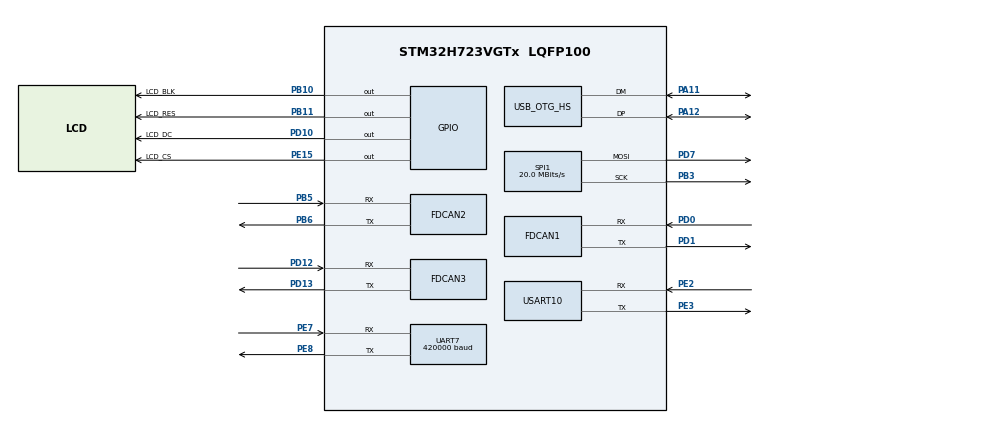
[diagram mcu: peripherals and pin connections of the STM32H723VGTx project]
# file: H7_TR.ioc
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CORTEX_M7.CPU_DCache=Enabled
CORTEX_M7.CPU_ICache=Enabled
CORTEX_M7.default_mode_Activation=1
FDCAN1.AutoRetransmission=ENABLE
FDCAN1.CalculateBaudRateNominal=1000000
FDCAN1.CalculateTimeBitNominal=1000
FDCAN1.CalculateTimeQuantumNominal=12.5
FDCAN1.DataPrescaler=1
FDCAN1.ExtFiltersNbr=4
FDCAN1.NominalPrescaler=1
FDCAN1.NominalSyncJumpWidth=20
FDCAN1.NominalTimeSeg1=59
FDCAN1.NominalTimeSeg2=20
FDCAN1.ProtocolException=ENABLE
FDCAN1.RxFifo0ElmtsNbr=8
FDCAN1.RxFifo1ElmtsNbr=8
FDCAN1.StdFiltersNbr=4
FDCAN1.TxFifoQueueElmtsNbr=8
FDCAN2.AutoRetransmission=ENABLE
FDCAN2.CalculateBaudRateNominal=1000000
FDCAN2.CalculateTimeBitNominal=1000
FDCAN2.CalculateTimeQuantumNominal=12.5
FDCAN2.ExtFiltersNbr=4
FDCAN2.MessageRAMOffset=1030
FDCAN2.NominalPrescaler=1
FDCAN2.NominalSyncJumpWidth=20
FDCAN2.NominalTimeSeg1=59
FDCAN2.NominalTimeSeg2=20
FDCAN2.ProtocolException=ENABLE
FDCAN2.RxFifo0ElmtsNbr=8
FDCAN2.RxFifo1ElmtsNbr=8
FDCAN2.StdFiltersNbr=4
FDCAN2.TxFifoQueueElmtsNbr=8
FDCAN3.AutoRetransmission=ENABLE
FDCAN3.CalculateBaudRateNominal=1000000
FDCAN3.CalculateTimeBitNominal=1000
FDCAN3.CalculateTimeQuantumNominal=12.5
FDCAN3.ExtFiltersNbr=4
FDCAN3.MessageRAMOffset=2066
FDCAN3.NominalPrescaler=1
FDCAN3.NominalSyncJumpWidth=20
FDCAN3.NominalTimeSeg1=59
FDCAN3.NominalTimeSeg2=20
FDCAN3.ProtocolException=ENABLE
FDCAN3.RxFifo0ElmtsNbr=8
FDCAN3.RxFifo1ElmtsNbr=8
FDCAN3.StdFiltersNbr=4
FDCAN3.TxFifoQueueElmtsNbr=8
Mcu.Family=STM32H7
Mcu.Name=STM32H723VGTx
Mcu.Package=LQFP100
NVIC.FDCAN1_IT0_IRQn=true\:0\:0\:false\:false\:true\:true\:true\:true
NVIC.FDCAN2_IT0_IRQn=true\:0\:0\:false\:false\:true\:true\:true\:true
NVIC.FDCAN3_IT0_IRQn=true\:0\:0\:false\:false\:true\:true\:true\:true
NVIC.OTG_HS_IRQn=true\:0\:0\:false\:false\:true\:false\:true\:true
NVIC.PriorityGroup=NVIC_PRIORITYGROUP_4
NVIC.TIM6_DAC_IRQn=true\:1\:0\:true\:false\:true\:true\:true\:true
NVIC.UART7_IRQn=true\:0\:0\:false\:false\:true\:true\:true\:true
NVIC.USART10_IRQn=true\:0\:0\:false\:false\:true\:true\:true\:true
PA11.Mode=Device_Only_FS
PA11.Signal=USB_OTG_HS_DM
PA12.Mode=Device_Only_FS
PA12.Signal=USB_OTG_HS_DP
PA13(JTMS/SWDIO).Mode=Serial_Wire
PA13(JTMS/SWDIO).Signal=DEBUG_JTMS-SWDIO
PA14(JTCK/SWCLK).Mode=Serial_Wire
PA14(JTCK/SWCLK).Signal=DEBUG_JTCK-SWCLK
PB10.GPIO_Label=LCD_BLK
PB10.GPIO_PuPd=GPIO_NOPULL
PB10.Signal=GPIO_Output
PB11.GPIO_Label=LCD_RES
PB11.PinState=GPIO_PIN_SET
PB11.Signal=GPIO_Output
PB3(JTDO/TRACESWO).Mode=TX_Only_Simplex_Unidirect_Master
PB3(JTDO/TRACESWO).Signal=SPI1_SCK
PB5.Mode=FDCAN_Activate
PB5.Signal=FDCAN2_RX
PB6.Mode=FDCAN_Activate
PB6.Signal=FDCAN2_TX
PD0.Mode=FDCAN_Activate
PD0.Signal=FDCAN1_RX
PD1.Mode=FDCAN_Activate
PD1.Signal=FDCAN1_TX
PD10.GPIO_Label=LCD_DC
PD10.GPIO_Speed=GPIO_SPEED_FREQ_VERY_HIGH
PD10.PinState=GPIO_PIN_SET
PD10.Signal=GPIO_Output
PD12.Mode=FDCAN_Activate
PD12.Signal=FDCAN3_RX
PD13.Mode=FDCAN_Activate
PD13.Signal=FDCAN3_TX
PD7.Mode=TX_Only_Simplex_Unidirect_Master
PD7.Signal=SPI1_MOSI
PE15.GPIO_Label=LCD_CS
PE15.GPIO_Speed=GPIO_SPEED_FREQ_VERY_HIGH
PE15.PinState=GPIO_PIN_SET
PE15.Signal=GPIO_Output
PE2.GPIO_PuPd=GPIO_PULLUP
PE2.Mode=Asynchronous
PE2.Signal=USART10_RX
PE3.Mode=Asynchronous
PE3.Signal=USART10_TX
PE7.GPIO_PuPd=GPIO_PULLUP
PE7.Mode=Asynchronous
PE7.Signal=UART7_RX
PE8.Mode=Asynchronous
PE8.Signal=UART7_TX
PH0-OSC_IN.Mode=HSE-External-Oscillator
PH0-OSC_IN.Signal=RCC_OSC_IN
PH1-OSC_OUT.Mode=HSE-External-Oscillator
PH1-OSC_OUT.Signal=RCC_OSC_OUT
ProjectManager.HeapSize=0x1000
ProjectManager.StackSize=0x1000
ProjectManager.TargetToolchain=CMake
RCC.ADCFreq_Value=48375000
RCC.APB1Freq_Value=120000000
RCC.APB2Freq_Value=120000000
RCC.APB3Freq_Value=120000000
RCC.APB4Freq_Value=120000000
RCC.CortexFreq_Value=480000000
RCC.D1PPRE=RCC_APB3_DIV2
RCC.D2PPRE1=RCC_APB1_DIV2
RCC.D2PPRE2=RCC_APB2_DIV2
RCC.D3PPRE=RCC_APB4_DIV2
RCC.DIVM1=2
RCC.DIVN1=40
RCC.DIVP1=1
RCC.DIVQ1=6
RCC.HCLKFreq_Value=240000000
RCC.HPRE=RCC_HCLK_DIV2
RCC.HSE_VALUE=24000000
RCC.PLLFRACN=0
RCC.PLLSourceVirtual=RCC_PLLSOURCE_HSE
RCC.SYSCLKFreq_VALUE=480000000
RCC.SYSCLKSource=RCC_SYSCLKSOURCE_PLLCLK
RCC.USBCLockSelection=RCC_USBCLKSOURCE_HSI48
RCC.USBFreq_Value=48000000
SPI1.BaudRatePrescaler=SPI_BAUDRATEPRESCALER_4
SPI1.CLKPolarity=SPI_POLARITY_HIGH
SPI1.CalculateBaudRate=20.0 MBits/s
SPI1.DataSize=SPI_DATASIZE_8BIT
SPI1.Direction=SPI_DIRECTION_2LINES_TXONLY
SPI1.MasterKeepIOState=SPI_MASTER_KEEP_IO_STATE_ENABLE
SPI1.Mode=SPI_MODE_MASTER
SPI1.VirtualType=VM_MASTER
TIM6.AutoReloadPreload=TIM_AUTORELOAD_PRELOAD_ENABLE
TIM6.Period=999
TIM6.Prescaler=239
UART7.BaudRate=420000
USART10.VirtualMode=VM_ASYNC
USB_DEVICE.CLASS_NAME_HS=CDC
USB_DEVICE.VirtualMode=Cdc
USB_DEVICE.VirtualModeHS=Cdc_HS
USB_OTG_HS.VirtualMode-Device_Only_FS=Device_Only_FS
VP_MEMORYMAP_VS_MEMORYMAP.Mode=CurAppReg
VP_TIM6_VS_ClockSourceINT.Mode=Enable_Timer
VP_USB_DEVICE_VS_USB_DEVICE_CDC_HS.Mode=CDC_HS
board=custom

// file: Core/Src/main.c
/* USER CODE BEGIN Header */
/**
 ******************************************************************************
 * @file           : main.c
 * @brief          : Main program body
 ******************************************************************************
 * @attention
 *
 * Copyright (c) 2026 STMicroelectronics.
 * All rights reserved.
 *wawa
 * This software is licensed under terms that can be found in the LICENSE file
 * in the root directory of this software component.
 * If no LICENSE file comes with this software, it is provided AS-IS.
 *
 ******************************************************************************
 */
/* USER CODE END Header */
#include "main.h"
#include "usb_device.h"

/* USER CODE BEGIN Includes */
#include "J4340.h"
#include "app_main.h"
#include "motor_cfg.h"
#include "motor_ctrl.h"
/* USER CODE END Includes */

FDCAN_HandleTypeDef hfdcan1;
FDCAN_HandleTypeDef hfdcan2;
FDCAN_HandleTypeDef hfdcan3;

SPI_HandleTypeDef hspi1;

TIM_HandleTypeDef htim6;

UART_HandleTypeDef huart7;
UART_HandleTypeDef huart10;

void SystemClock_Config(void);
static void MPU_Config(void);
static void MX_GPIO_Init(void);
static void MX_FDCAN1_Init(void);
static void MX_FDCAN2_Init(void);
static void MX_FDCAN3_Init(void);
static void MX_TIM6_Init(void);
static void MX_SPI1_Init(void);
static void MX_UART7_Init(void);
static void MX_USART10_UART_Init(void);

int main(void) {

  /* MPU Configuration--------------------------------------------------------*/
  MPU_Config();

  /* Enable the CPU Cache */

  /* Enable I-Cache---------------------------------------------------------*/
  SCB_EnableICache();

  /* Enable D-Cache---------------------------------------------------------*/
  SCB_EnableDCache();

  /* MCU Configuration--------------------------------------------------------*/

  /* Reset of all peripherals, Initializes the Flash interface and the Systick.
   */
  HAL_Init();

  /* Configure the system clock */
  SystemClock_Config();

  /* Initialize all configured peripherals */
  MX_GPIO_Init();
  MX_FDCAN1_Init();
  MX_FDCAN2_Init();
  MX_FDCAN3_Init();
  MX_USB_DEVICE_Init();
  MX_TIM6_Init();
  MX_SPI1_Init();
  MX_UART7_Init();
  MX_USART10_UART_Init();
  /* USER CODE BEGIN 2 */
  app_init();
  FDCAN1_Filter_Init();
  DM4340_Init();
  /* USER CODE END 2 */

  /* Infinite loop */
  while (1) {

    /* USER CODE BEGIN 3 */
    app_loop();
    DM4340_Task();
    // motor_ctrl_set_pos(MOTOR_M2006_1, 90.0f, 30.0f);
  }
  /* USER CODE END 3 */
}

void SystemClock_Config(void) {
  RCC_OscInitTypeDef RCC_OscInitStruct = {0};
  RCC_ClkInitTypeDef RCC_ClkInitStruct = {0};

  /** Supply configuration update enable
   */
  HAL_PWREx_ConfigSupply(PWR_LDO_SUPPLY);

  /** Configure the main internal regulator output voltage
   */
  __HAL_PWR_VOLTAGESCALING_CONFIG(PWR_REGULATOR_VOLTAGE_SCALE0);

  while (!__HAL_PWR_GET_FLAG(PWR_FLAG_VOSRDY)) {
  }

  /** Initializes the RCC Oscillators according to the specified parameters
   * in the RCC_OscInitTypeDef structure.
   */
  RCC_OscInitStruct.OscillatorType =
      RCC_OSCILLATORTYPE_HSI48 | RCC_OSCILLATORTYPE_HSE;
  RCC_OscInitStruct.HSEState = RCC_HSE_ON;
  RCC_OscInitStruct.HSI48State = RCC_HSI48_ON;
  RCC_OscInitStruct.PLL.PLLState = RCC_PLL_ON;
  RCC_OscInitStruct.PLL.PLLSource = RCC_PLLSOURCE_HSE;
  RCC_OscInitStruct.PLL.PLLM = 2;
  RCC_OscInitStruct.PLL.PLLN = 40;
  RCC_OscInitStruct.PLL.PLLP = 1;
  RCC_OscInitStruct.PLL.PLLQ = 6;
  RCC_OscInitStruct.PLL.PLLR = 2;
  RCC_OscInitStruct.PLL.PLLRGE = RCC_PLL1VCIRANGE_3;
  RCC_OscInitStruct.PLL.PLLVCOSEL = RCC_PLL1VCOWIDE;
  RCC_OscInitStruct.PLL.PLLFRACN = 0;
  if (HAL_RCC_OscConfig(&RCC_OscInitStruct) != HAL_OK) {
    Error_Handler();
  }

  /** Initializes the CPU, AHB and APB buses clocks
   */
  RCC_ClkInitStruct.ClockType = RCC_CLOCKTYPE_HCLK | RCC_CLOCKTYPE_SYSCLK |
                                RCC_CLOCKTYPE_PCLK1 | RCC_CLOCKTYPE_PCLK2 |
                                RCC_CLOCKTYPE_D3PCLK1 | RCC_CLOCKTYPE_D1PCLK1;
  RCC_ClkInitStruct.SYSCLKSource = RCC_SYSCLKSOURCE_PLLCLK;
  RCC_ClkInitStruct.SYSCLKDivider = RCC_SYSCLK_DIV1;
  RCC_ClkInitStruct.AHBCLKDivider = RCC_HCLK_DIV2;
  RCC_ClkInitStruct.APB3CLKDivider = RCC_APB3_DIV2;
  RCC_ClkInitStruct.APB1CLKDivider = RCC_APB1_DIV2;
  RCC_ClkInitStruct.APB2CLKDivider = RCC_APB2_DIV2;
  RCC_ClkInitStruct.APB4CLKDivider = RCC_APB4_DIV2;

  if (HAL_RCC_ClockConfig(&RCC_ClkInitStruct, FLASH_LATENCY_3) != HAL_OK) {
    Error_Handler();
  }
}

static void MX_FDCAN1_Init(void) {

  hfdcan1.Instance = FDCAN1;
  hfdcan1.Init.FrameFormat = FDCAN_FRAME_CLASSIC;
  hfdcan1.Init.Mode = FDCAN_MODE_NORMAL;
  hfdcan1.Init.AutoRetransmission = ENABLE;
  hfdcan1.Init.TransmitPause = DISABLE;
  hfdcan1.Init.ProtocolException = ENABLE;
  hfdcan1.Init.NominalPrescaler = 1;
  hfdcan1.Init.NominalSyncJumpWidth = 20;
  hfdcan1.Init.NominalTimeSeg1 = 59;
  hfdcan1.Init.NominalTimeSeg2 = 20;
  hfdcan1.Init.DataPrescaler = 1;
  hfdcan1.Init.DataSyncJumpWidth = 1;
  hfdcan1.Init.DataTimeSeg1 = 1;
  hfdcan1.Init.DataTimeSeg2 = 1;
  hfdcan1.Init.MessageRAMOffset = 0;
  hfdcan1.Init.StdFiltersNbr = 4;
  hfdcan1.Init.ExtFiltersNbr = 4;
  hfdcan1.Init.RxFifo0ElmtsNbr = 8;
  hfdcan1.Init.RxFifo0ElmtSize = FDCAN_DATA_BYTES_8;
  hfdcan1.Init.RxFifo1ElmtsNbr = 8;
  hfdcan1.Init.RxFifo1ElmtSize = FDCAN_DATA_BYTES_8;
  hfdcan1.Init.RxBuffersNbr = 0;
  hfdcan1.Init.RxBufferSize = FDCAN_DATA_BYTES_8;
  hfdcan1.Init.TxEventsNbr = 0;
  hfdcan1.Init.TxBuffersNbr = 0;
  hfdcan1.Init.TxFifoQueueElmtsNbr = 8;
  hfdcan1.Init.TxFifoQueueMode = FDCAN_TX_FIFO_OPERATION;
  hfdcan1.Init.TxElmtSize = FDCAN_DATA_BYTES_8;
  if (HAL_FDCAN_Init(&hfdcan1) != HAL_OK) {
    Error_Handler();
  }
}

static void MX_FDCAN2_Init(void) {

  hfdcan2.Instance = FDCAN2;
  hfdcan2.Init.FrameFormat = FDCAN_FRAME_CLASSIC;
  hfdcan2.Init.Mode = FDCAN_MODE_NORMAL;
  hfdcan2.Init.AutoRetransmission = ENABLE;
  hfdcan2.Init.TransmitPause = DISABLE;
  hfdcan2.Init.ProtocolException = ENABLE;
  hfdcan2.Init.NominalPrescaler = 1;
  hfdcan2.Init.NominalSyncJumpWidth = 20;
  hfdcan2.Init.NominalTimeSeg1 = 59;
  hfdcan2.Init.NominalTimeSeg2 = 20;
  hfdcan2.Init.DataPrescaler = 1;
  hfdcan2.Init.DataSyncJumpWidth = 1;
  hfdcan2.Init.DataTimeSeg1 = 1;
  hfdcan2.Init.DataTimeSeg2 = 1;
  hfdcan2.Init.MessageRAMOffset = 1030;
  hfdcan2.Init.StdFiltersNbr = 4;
  hfdcan2.Init.ExtFiltersNbr = 4;
  hfdcan2.Init.RxFifo0ElmtsNbr = 8;
  hfdcan2.Init.RxFifo0ElmtSize = FDCAN_DATA_BYTES_8;
  hfdcan2.Init.RxFifo1ElmtsNbr = 8;
  hfdcan2.Init.RxFifo1ElmtSize = FDCAN_DATA_BYTES_8;
  hfdcan2.Init.RxBuffersNbr = 0;
  hfdcan2.Init.RxBufferSize = FDCAN_DATA_BYTES_8;
  hfdcan2.Init.TxEventsNbr = 0;
  hfdcan2.Init.TxBuffersNbr = 0;
  hfdcan2.Init.TxFifoQueueElmtsNbr = 8;
  hfdcan2.Init.TxFifoQueueMode = FDCAN_TX_FIFO_OPERATION;
  hfdcan2.Init.TxElmtSize = FDCAN_DATA_BYTES_8;
  if (HAL_FDCAN_Init(&hfdcan2) != HAL_OK) {
    Error_Handler();
  }
}

static void MX_FDCAN3_Init(void) {

  hfdcan3.Instance = FDCAN3;
  hfdcan3.Init.FrameFormat = FDCAN_FRAME_CLASSIC;
  hfdcan3.Init.Mode = FDCAN_MODE_NORMAL;
  hfdcan3.Init.AutoRetransmission = ENABLE;
  hfdcan3.Init.TransmitPause = DISABLE;
  hfdcan3.Init.ProtocolException = ENABLE;
  hfdcan3.Init.NominalPrescaler = 1;
  hfdcan3.Init.NominalSyncJumpWidth = 20;
  hfdcan3.Init.NominalTimeSeg1 = 59;
  hfdcan3.Init.NominalTimeSeg2 = 20;
  hfdcan3.Init.DataPrescaler = 1;
  hfdcan3.Init.DataSyncJumpWidth = 1;
  hfdcan3.Init.DataTimeSeg1 = 1;
  hfdcan3.Init.DataTimeSeg2 = 1;
  hfdcan3.Init.MessageRAMOffset = 2066;
  hfdcan3.Init.StdFiltersNbr = 4;
  hfdcan3.Init.ExtFiltersNbr = 4;
  hfdcan3.Init.RxFifo0ElmtsNbr = 8;
  hfdcan3.Init.RxFifo0ElmtSize = FDCAN_DATA_BYTES_8;
  hfdcan3.Init.RxFifo1ElmtsNbr = 8;
  hfdcan3.Init.RxFifo1ElmtSize = FDCAN_DATA_BYTES_8;
  hfdcan3.Init.RxBuffersNbr = 0;
  hfdcan3.Init.RxBufferSize = FDCAN_DATA_BYTES_8;
  hfdcan3.Init.TxEventsNbr = 0;
  hfdcan3.Init.TxBuffersNbr = 0;
  hfdcan3.Init.TxFifoQueueElmtsNbr = 8;
  hfdcan3.Init.TxFifoQueueMode = FDCAN_TX_FIFO_OPERATION;
  hfdcan3.Init.TxElmtSize = FDCAN_DATA_BYTES_8;
  if (HAL_FDCAN_Init(&hfdcan3) != HAL_OK) {
    Error_Handler();
  }
}

static void MX_SPI1_Init(void) {

  /* SPI1 parameter configuration*/
  hspi1.Instance = SPI1;
  hspi1.Init.Mode = SPI_MODE_MASTER;
  hspi1.Init.Direction = SPI_DIRECTION_2LINES_TXONLY;
  hspi1.Init.DataSize = SPI_DATASIZE_8BIT;
  hspi1.Init.CLKPolarity = SPI_POLARITY_HIGH;
  hspi1.Init.CLKPhase = SPI_PHASE_1EDGE;
  hspi1.Init.NSS = SPI_NSS_SOFT;
  hspi1.Init.BaudRatePrescaler = SPI_BAUDRATEPRESCALER_4;
  hspi1.Init.FirstBit = SPI_FIRSTBIT_MSB;
  hspi1.Init.TIMode = SPI_TIMODE_DISABLE;
  hspi1.Init.CRCCalculation = SPI_CRCCALCULATION_DISABLE;
  hspi1.Init.CRCPolynomial = 0x0;
  hspi1.Init.NSSPMode = SPI_NSS_PULSE_ENABLE;
  hspi1.Init.NSSPolarity = SPI_NSS_POLARITY_LOW;
  hspi1.Init.FifoThreshold = SPI_FIFO_THRESHOLD_01DATA;
  hspi1.Init.TxCRCInitializationPattern =
      SPI_CRC_INITIALIZATION_ALL_ZERO_PATTERN;
  hspi1.Init.RxCRCInitializationPattern =
      SPI_CRC_INITIALIZATION_ALL_ZERO_PATTERN;
  hspi1.Init.MasterSSIdleness = SPI_MASTER_SS_IDLENESS_00CYCLE;
  hspi1.Init.MasterInterDataIdleness = SPI_MASTER_INTERDATA_IDLENESS_00CYCLE;
  hspi1.Init.MasterReceiverAutoSusp = SPI_MASTER_RX_AUTOSUSP_DISABLE;
  hspi1.Init.MasterKeepIOState = SPI_MASTER_KEEP_IO_STATE_ENABLE;
  hspi1.Init.IOSwap = SPI_IO_SWAP_DISABLE;
  if (HAL_SPI_Init(&hspi1) != HAL_OK) {
    Error_Handler();
  }
}

static void MX_TIM6_Init(void) {

  TIM_MasterConfigTypeDef sMasterConfig = {0};

  htim6.Instance = TIM6;
  htim6.Init.Prescaler = 239;
  htim6.Init.CounterMode = TIM_COUNTERMODE_UP;
  htim6.Init.Period = 999;
  htim6.Init.AutoReloadPreload = TIM_AUTORELOAD_PRELOAD_ENABLE;
  if (HAL_TIM_Base_Init(&htim6) != HAL_OK) {
    Error_Handler();
  }
  sMasterConfig.MasterOutputTrigger = TIM_TRGO_RESET;
  sMasterConfig.MasterSlaveMode = TIM_MASTERSLAVEMODE_DISABLE;
  if (HAL_TIMEx_MasterConfigSynchronization(&htim6, &sMasterConfig) != HAL_OK) {
    Error_Handler();
  }
}

static void MX_UART7_Init(void) {

  huart7.Instance = UART7;
  huart7.Init.BaudRate = 420000;
  huart7.Init.WordLength = UART_WORDLENGTH_8B;
  huart7.Init.StopBits = UART_STOPBITS_1;
  huart7.Init.Parity = UART_PARITY_NONE;
  huart7.Init.Mode = UART_MODE_TX_RX;
  huart7.Init.HwFlowCtl = UART_HWCONTROL_NONE;
  huart7.Init.OverSampling = UART_OVERSAMPLING_16;
  huart7.Init.OneBitSampling = UART_ONE_BIT_SAMPLE_DISABLE;
  huart7.Init.ClockPrescaler = UART_PRESCALER_DIV1;
  huart7.AdvancedInit.AdvFeatureInit = UART_ADVFEATURE_NO_INIT;
  if (HAL_UART_Init(&huart7) != HAL_OK) {
    Error_Handler();
  }
  if (HAL_UARTEx_SetTxFifoThreshold(&huart7, UART_TXFIFO_THRESHOLD_1_8) !=
      HAL_OK) {
    Error_Handler();
  }
  if (HAL_UARTEx_SetRxFifoThreshold(&huart7, UART_RXFIFO_THRESHOLD_1_8) !=
      HAL_OK) {
    Error_Handler();
  }
  if (HAL_UARTEx_DisableFifoMode(&huart7) != HAL_OK) {
    Error_Handler();
  }
}

static void MX_USART10_UART_Init(void) {

  huart10.Instance = USART10;
  huart10.Init.BaudRate = 115200;
  huart10.Init.WordLength = UART_WORDLENGTH_8B;
  huart10.Init.StopBits = UART_STOPBITS_1;
  huart10.Init.Parity = UART_PARITY_NONE;
  huart10.Init.Mode = UART_MODE_TX_RX;
  huart10.Init.HwFlowCtl = UART_HWCONTROL_NONE;
  huart10.Init.OverSampling = UART_OVERSAMPLING_16;
  huart10.Init.OneBitSampling = UART_ONE_BIT_SAMPLE_DISABLE;
  huart10.Init.ClockPrescaler = UART_PRESCALER_DIV1;
  huart10.AdvancedInit.AdvFeatureInit = UART_ADVFEATURE_NO_INIT;
  if (HAL_UART_Init(&huart10) != HAL_OK) {
    Error_Handler();
  }
  if (HAL_UARTEx_SetTxFifoThreshold(&huart10, UART_TXFIFO_THRESHOLD_1_8) !=
      HAL_OK) {
    Error_Handler();
  }
  if (HAL_UARTEx_SetRxFifoThreshold(&huart10, UART_RXFIFO_THRESHOLD_1_8) !=
      HAL_OK) {
    Error_Handler();
  }
  if (HAL_UARTEx_DisableFifoMode(&huart10) != HAL_OK) {
    Error_Handler();
  }
}

static void MX_GPIO_Init(void) {
  GPIO_InitTypeDef GPIO_InitStruct = {0};

  /* GPIO Ports Clock Enable */
  __HAL_RCC_GPIOE_CLK_ENABLE();
  __HAL_RCC_GPIOH_CLK_ENABLE();
  __HAL_RCC_GPIOB_CLK_ENABLE();
  __HAL_RCC_GPIOD_CLK_ENABLE();
  __HAL_RCC_GPIOA_CLK_ENABLE();

  /*Configure GPIO pin Output Level */
  HAL_GPIO_WritePin(LCD_CS_GPIO_Port, LCD_CS_Pin, GPIO_PIN_SET);

  /*Configure GPIO pin Output Level */
  HAL_GPIO_WritePin(LCD_BLK_GPIO_Port, LCD_BLK_Pin, GPIO_PIN_RESET);

  /*Configure GPIO pin Output Level */
  HAL_GPIO_WritePin(LCD_RES_GPIO_Port, LCD_RES_Pin, GPIO_PIN_SET);

  /*Configure GPIO pin Output Level */
  HAL_GPIO_WritePin(LCD_DC_GPIO_Port, LCD_DC_Pin, GPIO_PIN_SET);

  /*Configure GPIO pin : LCD_CS_Pin */
  GPIO_InitStruct.Pin = LCD_CS_Pin;
  GPIO_InitStruct.Mode = GPIO_MODE_OUTPUT_PP;
  GPIO_InitStruct.Pull = GPIO_NOPULL;
  GPIO_InitStruct.Speed = GPIO_SPEED_FREQ_VERY_HIGH;
  HAL_GPIO_Init(LCD_CS_GPIO_Port, &GPIO_InitStruct);

  /*Configure GPIO pins : LCD_BLK_Pin LCD_RES_Pin */
  GPIO_InitStruct.Pin = LCD_BLK_Pin | LCD_RES_Pin;
  GPIO_InitStruct.Mode = GPIO_MODE_OUTPUT_PP;
  GPIO_InitStruct.Pull = GPIO_NOPULL;
  GPIO_InitStruct.Speed = GPIO_SPEED_FREQ_LOW;
  HAL_GPIO_Init(GPIOB, &GPIO_InitStruct);

  /*Configure GPIO pin : LCD_DC_Pin */
  GPIO_InitStruct.Pin = LCD_DC_Pin;
  GPIO_InitStruct.Mode = GPIO_MODE_OUTPUT_PP;
  GPIO_InitStruct.Pull = GPIO_NOPULL;
  GPIO_InitStruct.Speed = GPIO_SPEED_FREQ_VERY_HIGH;
  HAL_GPIO_Init(LCD_DC_GPIO_Port, &GPIO_InitStruct);

}

/* MPU Configuration */

void MPU_Config(void) {
  MPU_Region_InitTypeDef MPU_InitStruct = {0};

  /* Disables the MPU */
  HAL_MPU_Disable();

  /** Initializes and configures the Region and the memory to be protected
   */
  MPU_InitStruct.Enable = MPU_REGION_ENABLE;
  MPU_InitStruct.Number = MPU_REGION_NUMBER0;
  MPU_InitStruct.BaseAddress = 0x0;
  MPU_InitStruct.Size = MPU_REGION_SIZE_4GB;
  MPU_InitStruct.SubRegionDisable = 0x87;
  MPU_InitStruct.TypeExtField = MPU_TEX_LEVEL0;
  MPU_InitStruct.AccessPermission = MPU_REGION_NO_ACCESS;
  MPU_InitStruct.DisableExec = MPU_INSTRUCTION_ACCESS_DISABLE;
  MPU_InitStruct.IsShareable = MPU_ACCESS_SHAREABLE;
  MPU_InitStruct.IsCacheable = MPU_ACCESS_NOT_CACHEABLE;
  MPU_InitStruct.IsBufferable = MPU_ACCESS_NOT_BUFFERABLE;

  HAL_MPU_ConfigRegion(&MPU_InitStruct);
  /* Enables the MPU */
  HAL_MPU_Enable(MPU_PRIVILEGED_DEFAULT);
}

void Error_Handler(void) {
  __disable_irq();
  while (1) {
  }
}
#ifdef USE_FULL_ASSERT
/**
 * @brief  Reports the name of the source file and the source line number
 *         where the assert_param error has occurred.
 * @param  file: pointer to the source file name
 * @param  line: assert_param error line source number
 * @retval None
 */
void assert_failed(uint8_t *file, uint32_t line) {
  /* USER CODE BEGIN 6 */
  /* User can add his own implementation to report the file name and line
     number, ex: printf("Wrong parameters value: file %s on line %d\r\n", file,
     line) */
  /* USER CODE END 6 */
}
#endif /* USE_FULL_ASSERT */
